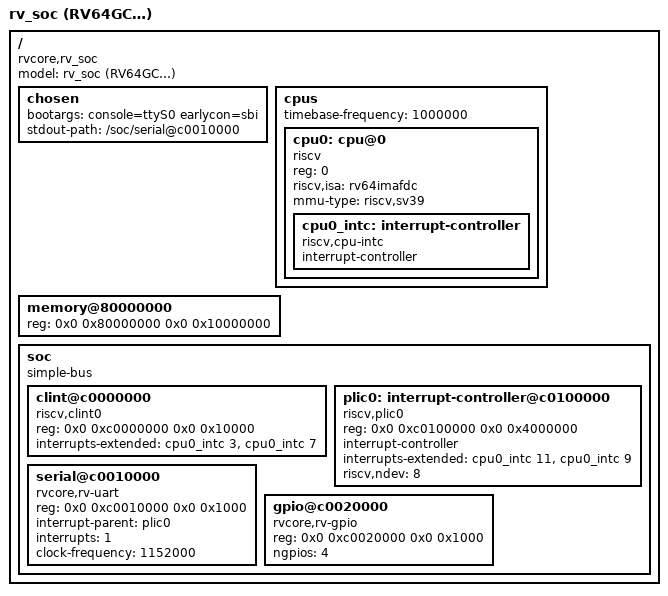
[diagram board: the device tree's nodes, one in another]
/dts-v1/;

/ {
    #address-cells = <2>;
    #size-cells = <2>;
    compatible = "rvcore,rv_soc";
    model = "rv_soc (RV64GC教育コア)";

    chosen {
        /* earlycon=sbi avoids needing a Linux UART driver before the console
         * node is probed.  Switch stdout-path to the uart once it has a driver. */
        bootargs = "console=ttyS0 earlycon=sbi";
        stdout-path = "/soc/serial@c0010000";
    };

    cpus {
        #address-cells = <1>;
        #size-cells = <0>;
        timebase-frequency = <1000000>;   /* CLINT mtime tick rate (match HW) */

        cpu0: cpu@0 {
            device_type = "cpu";
            reg = <0>;
            compatible = "riscv";
            riscv,isa = "rv64imafdc";
            mmu-type = "riscv,sv39";
            status = "okay";

            cpu0_intc: interrupt-controller {
                #interrupt-cells = <1>;
                interrupt-controller;
                compatible = "riscv,cpu-intc";
            };
        };
    };

    /* DRAM at the AXI/DDR base; size to the board's PS DDR (here: 256 MiB). */
    memory@80000000 {
        device_type = "memory";
        reg = <0x0 0x80000000  0x0 0x10000000>;
    };

    soc {
        #address-cells = <2>;
        #size-cells = <2>;
        compatible = "simple-bus";
        ranges;

        clint@c0000000 {
            compatible = "riscv,clint0";
            reg = <0x0 0xc0000000  0x0 0x10000>;
            interrupts-extended = <&cpu0_intc 3 &cpu0_intc 7>;  /* MSIP, MTIP */
        };

        plic0: interrupt-controller@c0100000 {
            compatible = "riscv,plic0";
            reg = <0x0 0xc0100000  0x0 0x4000000>;
            #interrupt-cells = <1>;
            interrupt-controller;
            interrupts-extended = <&cpu0_intc 11 &cpu0_intc 9>; /* MEIP, SEIP */
            riscv,ndev = <8>;
        };

        /* NOTE: rv_uart is a custom register layout with no upstream driver.
         * For OpenSBI/Linux console support make it 16550-compatible and set
         * compatible = "ns16550a" with reg-shift/reg-io-width, or write a driver.
         * See docs/opensbi_sim.md "Console caveat". */
        serial@c0010000 {
            compatible = "rvcore,rv-uart";
            reg = <0x0 0xc0010000  0x0 0x1000>;
            interrupt-parent = <&plic0>;
            interrupts = <1>;
            clock-frequency = <1152000>;
        };

        gpio@c0020000 {
            compatible = "rvcore,rv-gpio";
            reg = <0x0 0xc0020000  0x0 0x1000>;
            ngpios = <4>;
        };
    };
};
